# GD32M53x register map
File version: 1.0
CPU: CM33 r2p1, little endian, MPU, FPU, DSP, 4 interrupt priority bits
Registers are 32-bit, read-write, reset 0x0 unless marked. A register's access mark holds for its fields unless they carry their own. Offsets are from the block's base; [hi:lo] are bit positions; {n}, {i} and the like mark numbered series.

## POC — Port Output Controller
Base 0x48004400
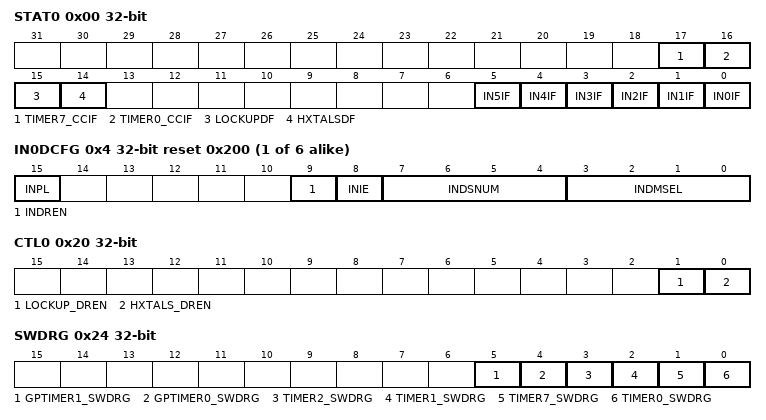
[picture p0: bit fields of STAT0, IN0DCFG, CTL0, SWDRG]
0x00 STAT0 — Status register 0
  [17] TIMER7_CCIF — TIMER7 concurrent conduction interrupt flag
  [16] TIMER0_CCIF — TIMER0 concurrent conduction interrupt flag
  [15] LOCKUPDF — CPU LOCKUP detection flag
  [14] HXTALSDF — HXTAL stuck detection flag
  [n] IN{n}IF (n=0..5) — POC_IN{n} input interrupt flag
{0x4+4i} IN{i}DCFG reset 0x200 (i=0..5) — Input n detection configuration regist {i}
  [15] INPL — Polarity of POC_INn pin input
  [9] INDREN — POC_INn disabling request enable
  [8] INIE — POC_INn input interrupt enable
  [7:4] INDSNUM — POC_INn input detection sampling number
  [3:0] INDMSEL — POC_INn input detection mode selection
0x20 CTL0 — Control register 0
  [1] LOCKUP_DREN — CPU LOCKUP disabling request enable
  [0] HXTALS_DREN — HXTAL stuck disabling request enable
0x24 SWDRG — Software disabling request generation register
  [5] GPTIMER1_SWDRG — Software disabling request generation for GPTIMER1
  [4] GPTIMER0_SWDRG — Software disabling request generation for GPTIMER0
  [3] TIMER2_SWDRG — Software disabling request generation for TIMER2
  [2] TIMER1_SWDRG — Software disabling request generation for TIMER1
  [1] TIMER7_SWDRG — Software disabling request generation for TIMER7
  [0] TIMER0_SWDRG — Software disabling request generation for TIMER0
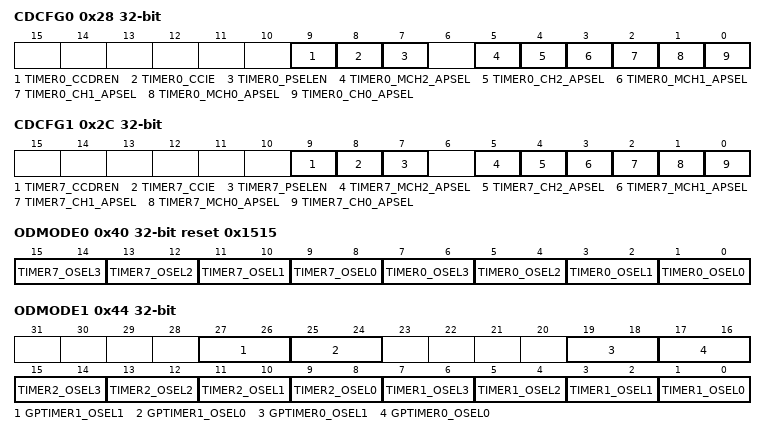
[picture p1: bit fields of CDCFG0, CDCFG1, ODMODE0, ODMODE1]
0x28 CDCFG0 — Complementary detection configuration register 0
  [9] TIMER0_CCDREN — TIMER0 concurrent conduction disabling request enable
  [8] TIMER0_CCIE — TIMER0 concurrent conduction interrupt enable
  [7] TIMER0_PSELEN — TIMER0 polarity selection enable
  [5] TIMER0_MCH2_APSEL — TIMER0_MCH2 active polarity selection
  [4] TIMER0_CH2_APSEL — TIMER0_CH2 active polarity selection
  [3] TIMER0_MCH1_APSEL — TIMER0_MCH1 active polarity selection
  [2] TIMER0_CH1_APSEL — TIMER0_CH1 active polarity selection
  [1] TIMER0_MCH0_APSEL — TIMER0_MCH0 active polarity selection
  [0] TIMER0_CH0_APSEL — TIMER0_CH0 active polarity selection
0x2C CDCFG1 — Complementary detection configuration register 1
  [9] TIMER7_CCDREN — TIMER7 concurrent conduction disabling request enable
  [8] TIMER7_CCIE — TIMER7 concurrent conduction interrupt enable
  [7] TIMER7_PSELEN — TIMER7 polarity selection enable
  [5] TIMER7_MCH2_APSEL — TIMER7_MCH2 active polarity selection
  [4] TIMER7_CH2_APSEL — TIMER7_CH2 active polarity selection
  [3] TIMER7_MCH1_APSEL — TIMER7_MCH1 active polarity selection
  [2] TIMER7_CH1_APSEL — TIMER7_CH1 active polarity selection
  [1] TIMER7_MCH0_APSEL — TIMER7_MCH0 active polarity selection
  [0] TIMER7_CH0_APSEL — TIMER7_CH0 active polarity selection
0x40 ODMODE0 reset 0x1515 — Output disable mode register 0
  [2n+9:2n+8] TIMER7_OSEL{n} (n=0..3) — Output selection for TIMER7_CH{n}/ TIMER7_MCH{n} pin
  [2n+1:2n] TIMER0_OSEL{n} (n=0..3) — Output selection for TIMER0_CH{n}/ TIMER0_MCH{n} pin
0x44 ODMODE1 — Output disable mode register 1
  [27:26] GPTIMER1_OSEL1 — Output selection for GPTIMER1_CH1 pin
  [25:24] GPTIMER1_OSEL0 — Output selection for GPTIMER1_CH0 pin
  [19:18] GPTIMER0_OSEL1 — Output selection for GPTIMER0_CH1 pin
  [17:16] GPTIMER0_OSEL0 — Output selection for GPTIMER0_CH0 pin
  [2n+9:2n+8] TIMER2_OSEL{n} (n=0..3) — Output selection for TIMER2_CH{n} pin
  [2n+1:2n] TIMER1_OSEL{n} (n=0..3) — Output selection for TIMER1_CH{n} pin
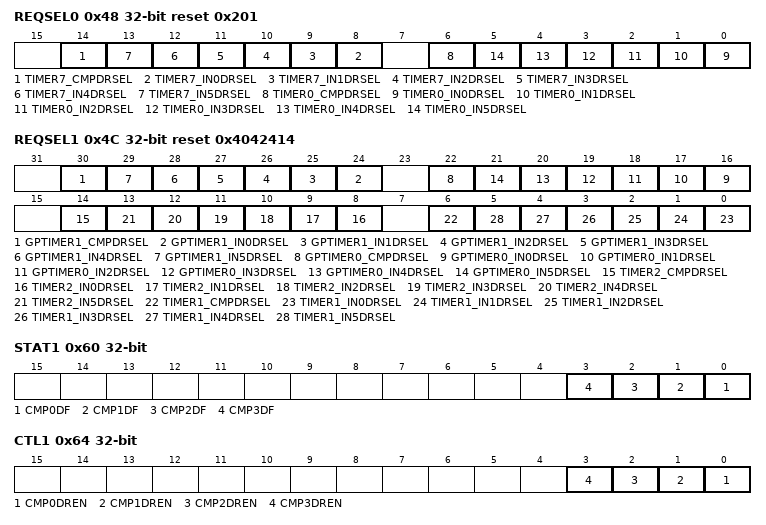
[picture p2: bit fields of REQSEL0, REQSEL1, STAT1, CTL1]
0x48 REQSEL0 reset 0x201 — Request selection register 0
  [14] TIMER7_CMPDRSEL — CMPn (n=0,1,2,3) disabling request select TIMER7
  [n+8] TIMER7_IN{n}DRSEL (n=0..5) — POC_IN{n} disabling request select TIMER7
  [6] TIMER0_CMPDRSEL — CMPn (n=0,1,2,3) disabling request select TIMER0
  [n] TIMER0_IN{n}DRSEL (n=0..5) — POC_IN{n} disabling request select TIMER0
0x4C REQSEL1 reset 0x4042414 — Request selection register 1
  [30] GPTIMER1_CMPDRSEL — CMPn (n=0,1,2,3) disabling request select GPTIMER1
  [n+24] GPTIMER1_IN{n}DRSEL (n=0..5) — POC_IN{n} disabling request select GPTIMER1
  [22] GPTIMER0_CMPDRSEL — CMPn (n=0,1,2,3) disabling request select GPTIMER0
  [n+16] GPTIMER0_IN{n}DRSEL (n=0..5) — POC_IN{n} disabling request select GPTIMER0
  [14] TIMER2_CMPDRSEL — CMPn (n=0,1,2,3) disabling request select TIMER2
  [n+8] TIMER2_IN{n}DRSEL (n=0..5) — POC_IN{n} disabling request select TIMER2
  [6] TIMER1_CMPDRSEL — CMPn (n=0,1,2,3) disabling request select TIMER1
  [n] TIMER1_IN{n}DRSEL (n=0..5) — POC_IN{n} disabling request select TIMER1
0x60 STAT1 — Status register 1
  [n] CMP{n}DF (n=0..3) — Comparator {n} detection flag
0x64 CTL1 — Control register 1
  [n] CMP{n}DREN (n=0..3) — Comparator {n} disabling request enable
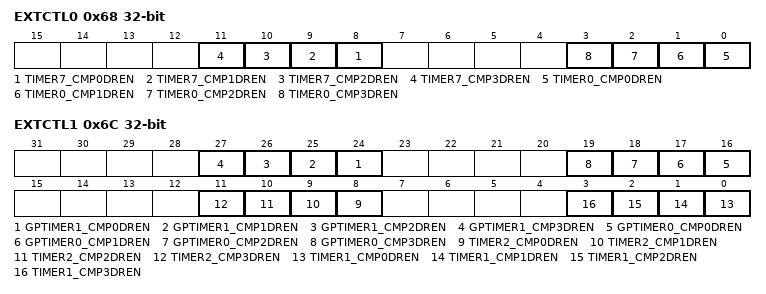
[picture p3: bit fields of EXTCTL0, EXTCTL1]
0x68 EXTCTL0 — Extended control register 0
  [n+8] TIMER7_CMP{n}DREN (n=0..3) — Comparator {n} disabling request enable for TIMER7
  [n] TIMER0_CMP{n}DREN (n=0..3) — Comparator {n} disabling request enable for TIMER0
0x6C EXTCTL1 — Extended control register 1
  [n+24] GPTIMER1_CMP{n}DREN (n=0..3) — Comparator {n} disabling request enable for GPTIMER1
  [n+16] GPTIMER0_CMP{n}DREN (n=0..3) — Comparator {n} disabling request enable for GPTIMER0
  [n+8] TIMER2_CMP{n}DREN (n=0..3) — Comparator {n} disabling request enable for TIMER2
  [n] TIMER1_CMP{n}DREN (n=0..3) — Comparator {n} disabling request enable for TIMER1
{0x70+4i} IN{i}DMK (i=0..5) — Input n detection mask regist {i}
  [4:0] INMKSEL — POC_INn input detection mask source selection
{0x90+4i} CMP{i}DMK (i=0..3) — Comparator n detection mask regist {i}
  [4:0] CMPMKSEL — Comparator n output detection mask source selection
